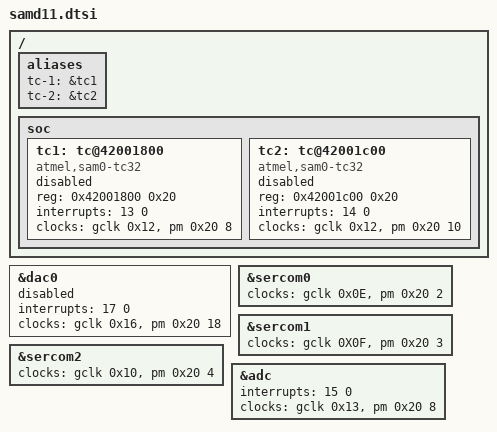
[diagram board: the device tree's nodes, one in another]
/*
 * Copyright (c) 2017 Google LLC.
 *
 * SPDX-License-Identifier: Apache-2.0
 */

 #include <atmel/samd1x.dtsi>

 / {
	aliases {
		tc-1 = &tc1;
		tc-2 = &tc2;
	};

	soc {
		tc1: tc@42001800 {
			compatible = "atmel,sam0-tc32";
			reg = <0x42001800 0x20>;
			interrupts = <13 0>;
			clocks = <&gclk 0x12>, <&pm 0x20 8>;
			clock-names = "GCLK", "PM";
			status = "disabled";
		};

		tc2: tc@42001c00 {
			compatible = "atmel,sam0-tc32";
			reg = <0x42001c00 0x20>;
			interrupts = <14 0>;
			clocks = <&gclk 0x12>, <&pm 0x20 10>;
			clock-names = "GCLK", "PM";
			status = "disabled";
		};
	};
};

&dac0 {
	interrupts = <17 0>;
	clocks = <&gclk 0x16>, <&pm 0x20 18>;
	clock-names = "GCLK", "PM";
	status = "disabled";
};

&sercom0 {
	clocks = <&gclk 0x0E>, <&pm 0x20 2>;
	clock-names = "GCLK", "PM";
	status = "okay";
};

&sercom1 {
	clocks = <&gclk 0X0F>, <&pm 0x20 3>;
	clock-names = "GCLK", "PM";
	status = "okay";
};

&sercom2 {
	clocks = <&gclk 0x10>, <&pm 0x20 4>;
	clock-names = "GCLK", "PM";
	status = "okay";
};


&adc {
	interrupts = <15 0>;
	interrupt-names = "resrdy";
	clocks = <&gclk 0x13>, <&pm 0x20 8>;
	clock-names = "GCLK", "PM";
	status = "okay";
};
